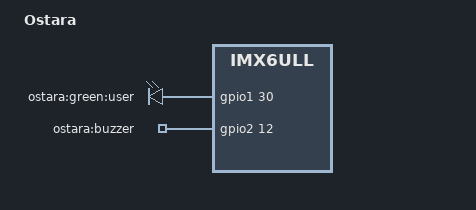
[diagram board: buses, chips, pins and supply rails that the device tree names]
// SPDX-License-Identifier: (GPL-2.0+ OR MIT)
// Copyright (C) 2017 Jagan Teki <jteki@openedev.com>

/dts-v1/;

#include "imx6ull.dtsi"

/ {
	model = "Ostara";
	compatible = "nke,imx6ull-ostara", "fsl,imx6ull";

	leds {
		compatible = "gpio-leds";

		led-0 {
			label = "ostara:green:user";
			gpios = <&gpio1 30 GPIO_ACTIVE_HIGH>;
			default-state = "on";
		};

		buzzer {
			label = "ostara:buzzer";
			gpios = <&gpio2 12 GPIO_ACTIVE_HIGH>;
			default-state = "off";
		};
	};
};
